# WKUP_ECC_AGGR0_REGS register map
Vendor: Texas Instruments
Peripheral module from a debugger description file (folder J721S2).
Registers are 32-bit, access not given, reset 0x0 unless marked. A register's access mark holds for its fields unless they carry their own. Offsets are as the file gives them; lines under a group give offsets from that group; [hi:lo] are bit positions; {n}, {i} and the like mark numbered series; 'fields as' and 'values as' point back to an identical list; <NAME> marks a mode.

## WKUP_ECC_AGGR0_REGS
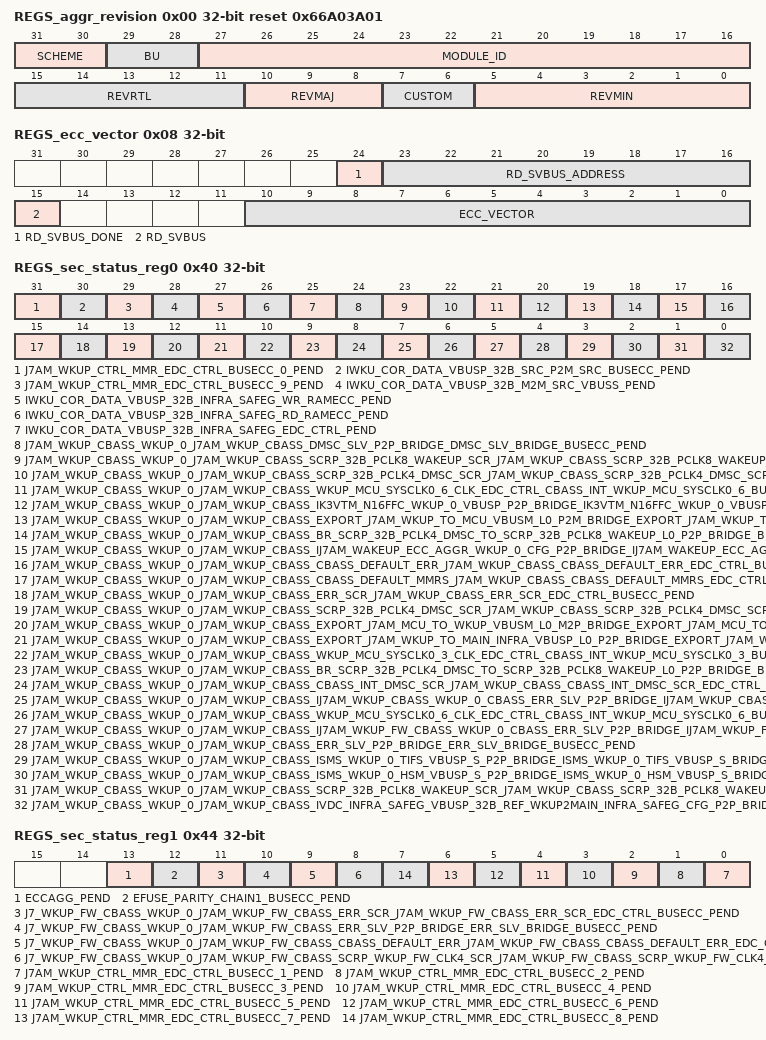
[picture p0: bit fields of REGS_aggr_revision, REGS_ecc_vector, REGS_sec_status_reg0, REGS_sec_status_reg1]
0x00 REGS_aggr_revision ro reset 0x66A03A01 — Revision parameters
  [31:30] SCHEME
  [29:28] BU
  [27:16] MODULE_ID
  [15:11] REVRTL — RTL version
  [10:8] REVMAJ — Major version
  [7:6] CUSTOM — Custom version
  [5:0] REVMIN — Minor version
0x08 REGS_ecc_vector — ECC Vector Register
  [24] RD_SVBUS_DONE — Status to indicate if read on serial VBUS is complete, write of any value will clear this bit. (access R/W1TC)
  [23:16] RD_SVBUS_ADDRESS rw — Read address
  [15] RD_SVBUS — Write 1 to trigger a read on the serial VBUS (access R/W1TS)
  [10:0] ECC_VECTOR rw — Value written to select the corresponding ECC RAM for control or status
0x0C REGS_misc_status ro reset 0x2E — Misc Status
  [10:0] NUM_RAMS — Indicates the number of RAMS serviced by the ECC aggregator
0x10 REGS_reserved_svbus rw — Reference other documents that contain the ECC RAM wrapper and EDC controller serial vbus register sets.
  [31:0] DATA — Serial VBUS register data
0x3C REGS_sec_eoi_reg — EOI Register
  [0] EOI_WR — EOI Register (access R/W1TS)
0x40 REGS_sec_status_reg0 — Interrupt Status Register 0
  [31] J7AM_WKUP_CTRL_MMR_EDC_CTRL_BUSECC_0_PEND — Interrupt Pending Status for j7am_wkup_ctrl_mmr_edc_ctrl_busecc_0_pend (access R/W1TS)
  [30] IWKU_COR_DATA_VBUSP_32B_SRC_P2M_SRC_BUSECC_PEND — Interrupt Pending Status for Iwku_cor_data_vbusp_32b_src_p2m_src_busecc_pend (access R/W1TS)
  [29] J7AM_WKUP_CTRL_MMR_EDC_CTRL_BUSECC_9_PEND — Interrupt Pending Status for j7am_wkup_ctrl_mmr_edc_ctrl_busecc_9_pend (access R/W1TS)
  [28] IWKU_COR_DATA_VBUSP_32B_M2M_SRC_VBUSS_PEND — Interrupt Pending Status for Iwku_cor_data_vbusp_32b_m2m_src_vbuss_pend (access R/W1TS)
  [27] IWKU_COR_DATA_VBUSP_32B_INFRA_SAFEG_WR_RAMECC_PEND — Interrupt Pending Status for Iwku_cor_data_vbusp_32b_infra_safeg_wr_ramecc_pend (access R/W1TS)
  [26] IWKU_COR_DATA_VBUSP_32B_INFRA_SAFEG_RD_RAMECC_PEND — Interrupt Pending Status for Iwku_cor_data_vbusp_32b_infra_safeg_rd_ramecc_pend (access R/W1TS)
  [25] IWKU_COR_DATA_VBUSP_32B_INFRA_SAFEG_EDC_CTRL_PEND — Interrupt Pending Status for Iwku_cor_data_vbusp_32b_infra_safeg_edc_ctrl_pend (access R/W1TS)
  [24] J7AM_WKUP_CBASS_WKUP_0_J7AM_WKUP_CBASS_DMSC_SLV_P2P_BRIDGE_DMSC_SLV_BRIDGE_BUSECC_PEND — Interrupt Pending Status for j7am_wkup_cbass_wkup_0_j7am_wkup_cbass_dmsc_slv_p2p_bridge_dmsc_slv_bridge_busecc_pend (access R/W1TS)
  [23] J7AM_WKUP_CBASS_WKUP_0_J7AM_WKUP_CBASS_SCRP_32B_PCLK8_WAKEUP_SCR_J7AM_WKUP_CBASS_SCRP_32B_PCLK8_WAKEUP_SCR_EDC_CTRL_BUSECC_0_PEND — Interrupt Pending Status for j7am_wkup_cbass_wkup_0_j7am_wkup_cbass_SCRP_32b_PCLK8_wakeup_scr_j7am_wkup_cbass_SCRP_32b_PCLK8_wakeup_scr_edc_ctrl_busecc_0_pend (access R/W1TS)
  [22] J7AM_WKUP_CBASS_WKUP_0_J7AM_WKUP_CBASS_SCRP_32B_PCLK4_DMSC_SCR_J7AM_WKUP_CBASS_SCRP_32B_PCLK4_DMSC_SCR_EDC_CTRL_BUSECC_1_PEND — Interrupt Pending Status for j7am_wkup_cbass_wkup_0_j7am_wkup_cbass_SCRP_32b_PCLK4_DMSC_scr_j7am_wkup_cbass_SCRP_32b_PCLK4_DMSC_scr_edc_ctrl_busecc_1_pend (access R/W1TS)
  [21] J7AM_WKUP_CBASS_WKUP_0_J7AM_WKUP_CBASS_WKUP_MCU_SYSCLK0_6_CLK_EDC_CTRL_CBASS_INT_WKUP_MCU_SYSCLK0_6_BUSECC_1_PEND — Interrupt Pending Status for j7am_wkup_cbass_wkup_0_j7am_wkup_cbass_wkup_mcu_sysclk0_6_clk_edc_ctrl_cbass_int_wkup_mcu_sysclk0_6_busecc_1_pend (access R/W1TS)
  [20] J7AM_WKUP_CBASS_WKUP_0_J7AM_WKUP_CBASS_IK3VTM_N16FFC_WKUP_0_VBUSP_P2P_BRIDGE_IK3VTM_N16FFC_WKUP_0_VBUSP_BRIDGE_BUSECC_PEND — Interrupt Pending Status for j7am_wkup_cbass_wkup_0_j7am_wkup_cbass_Ik3vtm_n16ffc_wkup_0_vbusp_p2p_bridge_Ik3vtm_n16ffc_wkup_0_vbusp_bridge_busecc_pend (access R/W1TS)
  [19] J7AM_WKUP_CBASS_WKUP_0_J7AM_WKUP_CBASS_EXPORT_J7AM_WKUP_TO_MCU_VBUSM_L0_P2M_BRIDGE_EXPORT_J7AM_WKUP_TO_MCU_VBUSM_L0_BRIDGE_BUSECC_PEND — Interrupt Pending Status for j7am_wkup_cbass_wkup_0_j7am_wkup_cbass_export_j7am_wkup_to_mcu_vbusm_l0_p2m_bridge_export_j7am_wkup_to_mcu_vbusm_l0_bridge_busecc_pend (access R/W1TS)
  [18] J7AM_WKUP_CBASS_WKUP_0_J7AM_WKUP_CBASS_BR_SCRP_32B_PCLK4_DMSC_TO_SCRP_32B_PCLK8_WAKEUP_L0_P2P_BRIDGE_BR_SCRP_32B_PCLK4_DMSC_TO_SCRP_32B_PCLK8_WAKEUP_L0_BRIDGE_DST_BUSECC_PEND — Interrupt Pending Status for j7am_wkup_cbass_wkup_0_j7am_wkup_cbass_br_SCRP_32b_PCLK4_DMSC_to_SCRP_32b_PCLK8_wakeup_l0_p2p_bridge_br_SCRP_32b_PCLK4_DMSC_to_SCRP_32b_PCLK8_wakeup_l0_bridge_dst_busecc_pend (access R/W1TS)
  [17] J7AM_WKUP_CBASS_WKUP_0_J7AM_WKUP_CBASS_IJ7AM_WAKEUP_ECC_AGGR_WKUP_0_CFG_P2P_BRIDGE_IJ7AM_WAKEUP_ECC_AGGR_WKUP_0_CFG_BRIDGE_BUSECC_PEND — Interrupt Pending Status for j7am_wkup_cbass_wkup_0_j7am_wkup_cbass_Ij7am_wakeup_ecc_aggr_wkup_0_cfg_p2p_bridge_Ij7am_wakeup_ecc_aggr_wkup_0_cfg_bridge_busecc_pend (access R/W1TS)
  [16] J7AM_WKUP_CBASS_WKUP_0_J7AM_WKUP_CBASS_CBASS_DEFAULT_ERR_J7AM_WKUP_CBASS_CBASS_DEFAULT_ERR_EDC_CTRL_BUSECC_PEND — Interrupt Pending Status for j7am_wkup_cbass_wkup_0_j7am_wkup_cbass_cbass_default_err_j7am_wkup_cbass_cbass_default_err_edc_ctrl_busecc_pend (access R/W1TS)
  [15] J7AM_WKUP_CBASS_WKUP_0_J7AM_WKUP_CBASS_CBASS_DEFAULT_MMRS_J7AM_WKUP_CBASS_CBASS_DEFAULT_MMRS_EDC_CTRL_BUSECC_PEND — Interrupt Pending Status for j7am_wkup_cbass_wkup_0_j7am_wkup_cbass_cbass_default_mmrs_j7am_wkup_cbass_cbass_default_mmrs_edc_ctrl_busecc_pend (access R/W1TS)
  [14] J7AM_WKUP_CBASS_WKUP_0_J7AM_WKUP_CBASS_ERR_SCR_J7AM_WKUP_CBASS_ERR_SCR_EDC_CTRL_BUSECC_PEND — Interrupt Pending Status for j7am_wkup_cbass_wkup_0_j7am_wkup_cbass_err_scr_j7am_wkup_cbass_err_scr_edc_ctrl_busecc_pend (access R/W1TS)
  [13] J7AM_WKUP_CBASS_WKUP_0_J7AM_WKUP_CBASS_SCRP_32B_PCLK4_DMSC_SCR_J7AM_WKUP_CBASS_SCRP_32B_PCLK4_DMSC_SCR_EDC_CTRL_BUSECC_0_PEND — Interrupt Pending Status for j7am_wkup_cbass_wkup_0_j7am_wkup_cbass_SCRP_32b_PCLK4_DMSC_scr_j7am_wkup_cbass_SCRP_32b_PCLK4_DMSC_scr_edc_ctrl_busecc_0_pend (access R/W1TS)
  [12] J7AM_WKUP_CBASS_WKUP_0_J7AM_WKUP_CBASS_EXPORT_J7AM_MCU_TO_WKUP_VBUSM_L0_M2P_BRIDGE_EXPORT_J7AM_MCU_TO_WKUP_VBUSM_L0_BRIDGE_BUSECC_PEND — Interrupt Pending Status for j7am_wkup_cbass_wkup_0_j7am_wkup_cbass_export_j7am_mcu_to_wkup_vbusm_l0_m2p_bridge_export_j7am_mcu_to_wkup_vbusm_l0_bridge_busecc_pend (access R/W1TS)
  [11] J7AM_WKUP_CBASS_WKUP_0_J7AM_WKUP_CBASS_EXPORT_J7AM_WKUP_TO_MAIN_INFRA_VBUSP_L0_P2P_BRIDGE_EXPORT_J7AM_WKUP_TO_MAIN_INFRA_VBUSP_L0_BRIDGE_BUSECC_PEND — Interrupt Pending Status for j7am_wkup_cbass_wkup_0_j7am_wkup_cbass_export_j7am_wkup_to_main_infra_vbusp_l0_p2p_bridge_export_j7am_wkup_to_main_infra_vbusp_l0_bridge_busecc_pend (access R/W1TS)
  [10] J7AM_WKUP_CBASS_WKUP_0_J7AM_WKUP_CBASS_WKUP_MCU_SYSCLK0_3_CLK_EDC_CTRL_CBASS_INT_WKUP_MCU_SYSCLK0_3_BUSECC_PEND — Interrupt Pending Status for j7am_wkup_cbass_wkup_0_j7am_wkup_cbass_wkup_mcu_sysclk0_3_clk_edc_ctrl_cbass_int_wkup_mcu_sysclk0_3_busecc_pend (access R/W1TS)
  [9] J7AM_WKUP_CBASS_WKUP_0_J7AM_WKUP_CBASS_BR_SCRP_32B_PCLK4_DMSC_TO_SCRP_32B_PCLK8_WAKEUP_L0_P2P_BRIDGE_BR_SCRP_32B_PCLK4_DMSC_TO_SCRP_32B_PCLK8_WAKEUP_L0_BRIDGE_SRC_BUSECC_PEND — Interrupt Pending Status for j7am_wkup_cbass_wkup_0_j7am_wkup_cbass_br_SCRP_32b_PCLK4_DMSC_to_SCRP_32b_PCLK8_wakeup_l0_p2p_bridge_br_SCRP_32b_PCLK4_DMSC_to_SCRP_32b_PCLK8_wakeup_l0_bridge_src_busecc_pend (access R/W1TS)
  [8] J7AM_WKUP_CBASS_WKUP_0_J7AM_WKUP_CBASS_CBASS_INT_DMSC_SCR_J7AM_WKUP_CBASS_CBASS_INT_DMSC_SCR_EDC_CTRL_BUSECC_PEND — Interrupt Pending Status for j7am_wkup_cbass_wkup_0_j7am_wkup_cbass_cbass_int_dmsc_scr_j7am_wkup_cbass_cbass_int_dmsc_scr_edc_ctrl_busecc_pend (access R/W1TS)
  [7] J7AM_WKUP_CBASS_WKUP_0_J7AM_WKUP_CBASS_IJ7AM_WKUP_CBASS_WKUP_0_CBASS_ERR_SLV_P2P_BRIDGE_IJ7AM_WKUP_CBASS_WKUP_0_CBASS_ERR_SLV_BRIDGE_BUSECC_PEND — Interrupt Pending Status for j7am_wkup_cbass_wkup_0_j7am_wkup_cbass_Ij7am_wkup_cbass_wkup_0_cbass_err_slv_p2p_bridge_Ij7am_wkup_cbass_wkup_0_cbass_err_slv_bridge_busecc_pend (access R/W1TS)
  [6] J7AM_WKUP_CBASS_WKUP_0_J7AM_WKUP_CBASS_WKUP_MCU_SYSCLK0_6_CLK_EDC_CTRL_CBASS_INT_WKUP_MCU_SYSCLK0_6_BUSECC_0_PEND — Interrupt Pending Status for j7am_wkup_cbass_wkup_0_j7am_wkup_cbass_wkup_mcu_sysclk0_6_clk_edc_ctrl_cbass_int_wkup_mcu_sysclk0_6_busecc_0_pend (access R/W1TS)
  [5] J7AM_WKUP_CBASS_WKUP_0_J7AM_WKUP_CBASS_IJ7AM_WKUP_FW_CBASS_WKUP_0_CBASS_ERR_SLV_P2P_BRIDGE_IJ7AM_WKUP_FW_CBASS_WKUP_0_CBASS_ERR_SLV_BRIDGE_BUSECC_PEND — Interrupt Pending Status for j7am_wkup_cbass_wkup_0_j7am_wkup_cbass_Ij7am_wkup_fw_cbass_wkup_0_cbass_err_slv_p2p_bridge_Ij7am_wkup_fw_cbass_wkup_0_cbass_err_slv_bridge_busecc_pend (access R/W1TS)
  [4] J7AM_WKUP_CBASS_WKUP_0_J7AM_WKUP_CBASS_ERR_SLV_P2P_BRIDGE_ERR_SLV_BRIDGE_BUSECC_PEND — Interrupt Pending Status for j7am_wkup_cbass_wkup_0_j7am_wkup_cbass_err_slv_p2p_bridge_err_slv_bridge_busecc_pend (access R/W1TS)
  [3] J7AM_WKUP_CBASS_WKUP_0_J7AM_WKUP_CBASS_ISMS_WKUP_0_TIFS_VBUSP_S_P2P_BRIDGE_ISMS_WKUP_0_TIFS_VBUSP_S_BRIDGE_BUSECC_PEND — Interrupt Pending Status for j7am_wkup_cbass_wkup_0_j7am_wkup_cbass_Isms_wkup_0_tifs_vbusp_s_p2p_bridge_Isms_wkup_0_tifs_vbusp_s_bridge_busecc_pend (access R/W1TS)
  [2] J7AM_WKUP_CBASS_WKUP_0_J7AM_WKUP_CBASS_ISMS_WKUP_0_HSM_VBUSP_S_P2P_BRIDGE_ISMS_WKUP_0_HSM_VBUSP_S_BRIDGE_BUSECC_PEND — Interrupt Pending Status for j7am_wkup_cbass_wkup_0_j7am_wkup_cbass_Isms_wkup_0_hsm_vbusp_s_p2p_bridge_Isms_wkup_0_hsm_vbusp_s_bridge_busecc_pend (access R/W1TS)
  [1] J7AM_WKUP_CBASS_WKUP_0_J7AM_WKUP_CBASS_SCRP_32B_PCLK8_WAKEUP_SCR_J7AM_WKUP_CBASS_SCRP_32B_PCLK8_WAKEUP_SCR_EDC_CTRL_BUSECC_1_PEND — Interrupt Pending Status for j7am_wkup_cbass_wkup_0_j7am_wkup_cbass_SCRP_32b_PCLK8_wakeup_scr_j7am_wkup_cbass_SCRP_32b_PCLK8_wakeup_scr_edc_ctrl_busecc_1_pend (access R/W1TS)
  [0] J7AM_WKUP_CBASS_WKUP_0_J7AM_WKUP_CBASS_IVDC_INFRA_SAFEG_VBUSP_32B_REF_WKUP2MAIN_INFRA_SAFEG_CFG_P2P_BRIDGE_IVDC_INFRA_SAFEG_VBUSP_32B_REF_WKUP2MAIN_INFRA_SAFEG_CFG_BRIDGE_BUSECC_PEND — Interrupt Pending Status for j7am_wkup_cbass_wkup_0_j7am_wkup_cbass_Ivdc_infra_safeg_vbusp_32b_ref_wkup2main_infra_safeg_cfg_p2p_bridge_Ivdc_infra_safeg_vbusp_32b_ref_wkup2main_infra_safeg_cfg_bridge_busecc_pend (access R/W1TS)
0x44 REGS_sec_status_reg1 — Interrupt Status Register 1
  [13] ECCAGG_PEND — Interrupt Pending Status for eccagg_pend (access R/W1TS)
  [12] EFUSE_PARITY_CHAIN1_BUSECC_PEND — Interrupt Pending Status for efuse_parity_chain1_busecc_pend (access R/W1TS)
  [11] J7_WKUP_FW_CBASS_WKUP_0_J7AM_WKUP_FW_CBASS_ERR_SCR_J7AM_WKUP_FW_CBASS_ERR_SCR_EDC_CTRL_BUSECC_PEND — Interrupt Pending Status for j7_wkup_fw_cbass_wkup_0_j7am_wkup_fw_cbass_err_scr_j7am_wkup_fw_cbass_err_scr_edc_ctrl_busecc_pend (access R/W1TS)
  [10] J7_WKUP_FW_CBASS_WKUP_0_J7AM_WKUP_FW_CBASS_ERR_SLV_P2P_BRIDGE_ERR_SLV_BRIDGE_BUSECC_PEND — Interrupt Pending Status for j7_wkup_fw_cbass_wkup_0_j7am_wkup_fw_cbass_err_slv_p2p_bridge_err_slv_bridge_busecc_pend (access R/W1TS)
  [9] J7_WKUP_FW_CBASS_WKUP_0_J7AM_WKUP_FW_CBASS_CBASS_DEFAULT_ERR_J7AM_WKUP_FW_CBASS_CBASS_DEFAULT_ERR_EDC_CTRL_BUSECC_PEND — Interrupt Pending Status for j7_wkup_fw_cbass_wkup_0_j7am_wkup_fw_cbass_cbass_default_err_j7am_wkup_fw_cbass_cbass_default_err_edc_ctrl_busecc_pend (access R/W1TS)
  [8] J7_WKUP_FW_CBASS_WKUP_0_J7AM_WKUP_FW_CBASS_SCRP_WKUP_FW_CLK4_SCR_J7AM_WKUP_FW_CBASS_SCRP_WKUP_FW_CLK4_SCR_EDC_CTRL_BUSECC_PEND — Interrupt Pending Status for j7_wkup_fw_cbass_wkup_0_j7am_wkup_fw_cbass_SCRP_wkup_fw_CLK4_scr_j7am_wkup_fw_cbass_SCRP_wkup_fw_CLK4_scr_edc_ctrl_busecc_pend (access R/W1TS)
  [n-1] J7AM_WKUP_CTRL_MMR_EDC_CTRL_BUSECC_{n}_PEND (n=1..8) — Interrupt Pending Status for j7am_wkup_ctrl_mmr_edc_ctrl_busecc_{n}_pend (access R/W1TS)
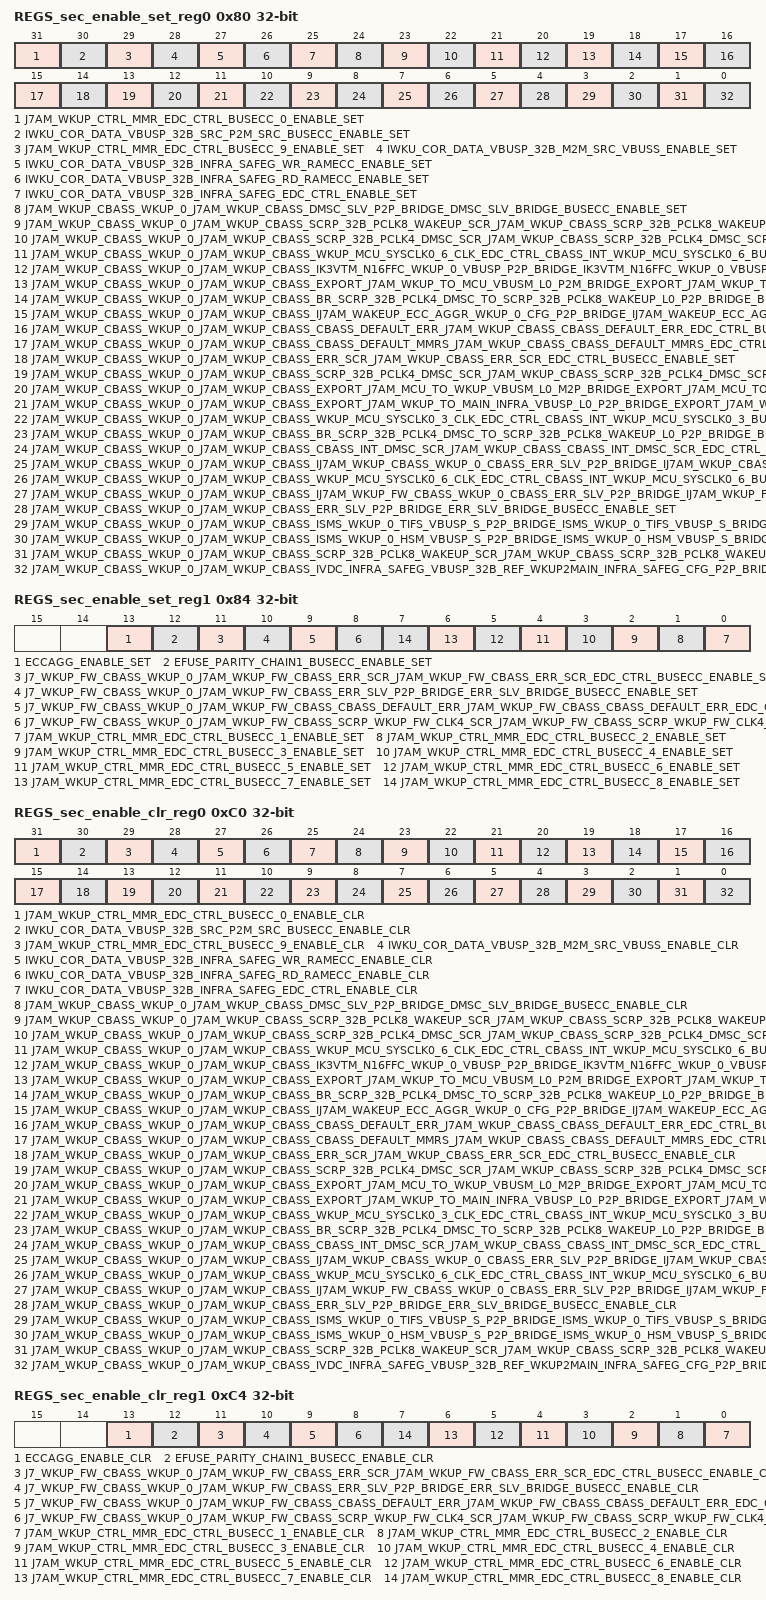
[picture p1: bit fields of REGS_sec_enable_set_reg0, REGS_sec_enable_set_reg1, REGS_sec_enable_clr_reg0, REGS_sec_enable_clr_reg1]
0x80 REGS_sec_enable_set_reg0 — Interrupt Enable Set Register 0
  [31] J7AM_WKUP_CTRL_MMR_EDC_CTRL_BUSECC_0_ENABLE_SET — Interrupt Enable Set Register for j7am_wkup_ctrl_mmr_edc_ctrl_busecc_0_pend (access R/W1TS)
  [30] IWKU_COR_DATA_VBUSP_32B_SRC_P2M_SRC_BUSECC_ENABLE_SET — Interrupt Enable Set Register for Iwku_cor_data_vbusp_32b_src_p2m_src_busecc_pend (access R/W1TS)
  [29] J7AM_WKUP_CTRL_MMR_EDC_CTRL_BUSECC_9_ENABLE_SET — Interrupt Enable Set Register for j7am_wkup_ctrl_mmr_edc_ctrl_busecc_9_pend (access R/W1TS)
  [28] IWKU_COR_DATA_VBUSP_32B_M2M_SRC_VBUSS_ENABLE_SET — Interrupt Enable Set Register for Iwku_cor_data_vbusp_32b_m2m_src_vbuss_pend (access R/W1TS)
  [27] IWKU_COR_DATA_VBUSP_32B_INFRA_SAFEG_WR_RAMECC_ENABLE_SET — Interrupt Enable Set Register for Iwku_cor_data_vbusp_32b_infra_safeg_wr_ramecc_pend (access R/W1TS)
  [26] IWKU_COR_DATA_VBUSP_32B_INFRA_SAFEG_RD_RAMECC_ENABLE_SET — Interrupt Enable Set Register for Iwku_cor_data_vbusp_32b_infra_safeg_rd_ramecc_pend (access R/W1TS)
  [25] IWKU_COR_DATA_VBUSP_32B_INFRA_SAFEG_EDC_CTRL_ENABLE_SET — Interrupt Enable Set Register for Iwku_cor_data_vbusp_32b_infra_safeg_edc_ctrl_pend (access R/W1TS)
  [24] J7AM_WKUP_CBASS_WKUP_0_J7AM_WKUP_CBASS_DMSC_SLV_P2P_BRIDGE_DMSC_SLV_BRIDGE_BUSECC_ENABLE_SET — Interrupt Enable Set Register for j7am_wkup_cbass_wkup_0_j7am_wkup_cbass_dmsc_slv_p2p_bridge_dmsc_slv_bridge_busecc_pend (access R/W1TS)
  [23] J7AM_WKUP_CBASS_WKUP_0_J7AM_WKUP_CBASS_SCRP_32B_PCLK8_WAKEUP_SCR_J7AM_WKUP_CBASS_SCRP_32B_PCLK8_WAKEUP_SCR_EDC_CTRL_BUSECC_0_ENABLE_SET — Interrupt Enable Set Register for j7am_wkup_cbass_wkup_0_j7am_wkup_cbass_SCRP_32b_PCLK8_wakeup_scr_j7am_wkup_cbass_SCRP_32b_PCLK8_wakeup_scr_edc_ctrl_busecc_0_pend (access R/W1TS)
  [22] J7AM_WKUP_CBASS_WKUP_0_J7AM_WKUP_CBASS_SCRP_32B_PCLK4_DMSC_SCR_J7AM_WKUP_CBASS_SCRP_32B_PCLK4_DMSC_SCR_EDC_CTRL_BUSECC_1_ENABLE_SET — Interrupt Enable Set Register for j7am_wkup_cbass_wkup_0_j7am_wkup_cbass_SCRP_32b_PCLK4_DMSC_scr_j7am_wkup_cbass_SCRP_32b_PCLK4_DMSC_scr_edc_ctrl_busecc_1_pend (access R/W1TS)
  [21] J7AM_WKUP_CBASS_WKUP_0_J7AM_WKUP_CBASS_WKUP_MCU_SYSCLK0_6_CLK_EDC_CTRL_CBASS_INT_WKUP_MCU_SYSCLK0_6_BUSECC_1_ENABLE_SET — Interrupt Enable Set Register for j7am_wkup_cbass_wkup_0_j7am_wkup_cbass_wkup_mcu_sysclk0_6_clk_edc_ctrl_cbass_int_wkup_mcu_sysclk0_6_busecc_1_pend (access R/W1TS)
  [20] J7AM_WKUP_CBASS_WKUP_0_J7AM_WKUP_CBASS_IK3VTM_N16FFC_WKUP_0_VBUSP_P2P_BRIDGE_IK3VTM_N16FFC_WKUP_0_VBUSP_BRIDGE_BUSECC_ENABLE_SET — Interrupt Enable Set Register for j7am_wkup_cbass_wkup_0_j7am_wkup_cbass_Ik3vtm_n16ffc_wkup_0_vbusp_p2p_bridge_Ik3vtm_n16ffc_wkup_0_vbusp_bridge_busecc_pend (access R/W1TS)
  [19] J7AM_WKUP_CBASS_WKUP_0_J7AM_WKUP_CBASS_EXPORT_J7AM_WKUP_TO_MCU_VBUSM_L0_P2M_BRIDGE_EXPORT_J7AM_WKUP_TO_MCU_VBUSM_L0_BRIDGE_BUSECC_ENABLE_SET — Interrupt Enable Set Register for j7am_wkup_cbass_wkup_0_j7am_wkup_cbass_export_j7am_wkup_to_mcu_vbusm_l0_p2m_bridge_export_j7am_wkup_to_mcu_vbusm_l0_bridge_busecc_pend (access R/W1TS)
  [18] J7AM_WKUP_CBASS_WKUP_0_J7AM_WKUP_CBASS_BR_SCRP_32B_PCLK4_DMSC_TO_SCRP_32B_PCLK8_WAKEUP_L0_P2P_BRIDGE_BR_SCRP_32B_PCLK4_DMSC_TO_SCRP_32B_PCLK8_WAKEUP_L0_BRIDGE_DST_BUSECC_ENABLE_SET — Interrupt Enable Set Register for j7am_wkup_cbass_wkup_0_j7am_wkup_cbass_br_SCRP_32b_PCLK4_DMSC_to_SCRP_32b_PCLK8_wakeup_l0_p2p_bridge_br_SCRP_32b_PCLK4_DMSC_to_SCRP_32b_PCLK8_wakeup_l0_bridge_dst_busecc_pend (access R/W1TS)
  [17] J7AM_WKUP_CBASS_WKUP_0_J7AM_WKUP_CBASS_IJ7AM_WAKEUP_ECC_AGGR_WKUP_0_CFG_P2P_BRIDGE_IJ7AM_WAKEUP_ECC_AGGR_WKUP_0_CFG_BRIDGE_BUSECC_ENABLE_SET — Interrupt Enable Set Register for j7am_wkup_cbass_wkup_0_j7am_wkup_cbass_Ij7am_wakeup_ecc_aggr_wkup_0_cfg_p2p_bridge_Ij7am_wakeup_ecc_aggr_wkup_0_cfg_bridge_busecc_pend (access R/W1TS)
  [16] J7AM_WKUP_CBASS_WKUP_0_J7AM_WKUP_CBASS_CBASS_DEFAULT_ERR_J7AM_WKUP_CBASS_CBASS_DEFAULT_ERR_EDC_CTRL_BUSECC_ENABLE_SET — Interrupt Enable Set Register for j7am_wkup_cbass_wkup_0_j7am_wkup_cbass_cbass_default_err_j7am_wkup_cbass_cbass_default_err_edc_ctrl_busecc_pend (access R/W1TS)
  [15] J7AM_WKUP_CBASS_WKUP_0_J7AM_WKUP_CBASS_CBASS_DEFAULT_MMRS_J7AM_WKUP_CBASS_CBASS_DEFAULT_MMRS_EDC_CTRL_BUSECC_ENABLE_SET — Interrupt Enable Set Register for j7am_wkup_cbass_wkup_0_j7am_wkup_cbass_cbass_default_mmrs_j7am_wkup_cbass_cbass_default_mmrs_edc_ctrl_busecc_pend (access R/W1TS)
  [14] J7AM_WKUP_CBASS_WKUP_0_J7AM_WKUP_CBASS_ERR_SCR_J7AM_WKUP_CBASS_ERR_SCR_EDC_CTRL_BUSECC_ENABLE_SET — Interrupt Enable Set Register for j7am_wkup_cbass_wkup_0_j7am_wkup_cbass_err_scr_j7am_wkup_cbass_err_scr_edc_ctrl_busecc_pend (access R/W1TS)
  [13] J7AM_WKUP_CBASS_WKUP_0_J7AM_WKUP_CBASS_SCRP_32B_PCLK4_DMSC_SCR_J7AM_WKUP_CBASS_SCRP_32B_PCLK4_DMSC_SCR_EDC_CTRL_BUSECC_0_ENABLE_SET — Interrupt Enable Set Register for j7am_wkup_cbass_wkup_0_j7am_wkup_cbass_SCRP_32b_PCLK4_DMSC_scr_j7am_wkup_cbass_SCRP_32b_PCLK4_DMSC_scr_edc_ctrl_busecc_0_pend (access R/W1TS)
  [12] J7AM_WKUP_CBASS_WKUP_0_J7AM_WKUP_CBASS_EXPORT_J7AM_MCU_TO_WKUP_VBUSM_L0_M2P_BRIDGE_EXPORT_J7AM_MCU_TO_WKUP_VBUSM_L0_BRIDGE_BUSECC_ENABLE_SET — Interrupt Enable Set Register for j7am_wkup_cbass_wkup_0_j7am_wkup_cbass_export_j7am_mcu_to_wkup_vbusm_l0_m2p_bridge_export_j7am_mcu_to_wkup_vbusm_l0_bridge_busecc_pend (access R/W1TS)
  [11] J7AM_WKUP_CBASS_WKUP_0_J7AM_WKUP_CBASS_EXPORT_J7AM_WKUP_TO_MAIN_INFRA_VBUSP_L0_P2P_BRIDGE_EXPORT_J7AM_WKUP_TO_MAIN_INFRA_VBUSP_L0_BRIDGE_BUSECC_ENABLE_SET — Interrupt Enable Set Register for j7am_wkup_cbass_wkup_0_j7am_wkup_cbass_export_j7am_wkup_to_main_infra_vbusp_l0_p2p_bridge_export_j7am_wkup_to_main_infra_vbusp_l0_bridge_busecc_pend (access R/W1TS)
  [10] J7AM_WKUP_CBASS_WKUP_0_J7AM_WKUP_CBASS_WKUP_MCU_SYSCLK0_3_CLK_EDC_CTRL_CBASS_INT_WKUP_MCU_SYSCLK0_3_BUSECC_ENABLE_SET — Interrupt Enable Set Register for j7am_wkup_cbass_wkup_0_j7am_wkup_cbass_wkup_mcu_sysclk0_3_clk_edc_ctrl_cbass_int_wkup_mcu_sysclk0_3_busecc_pend (access R/W1TS)
  [9] J7AM_WKUP_CBASS_WKUP_0_J7AM_WKUP_CBASS_BR_SCRP_32B_PCLK4_DMSC_TO_SCRP_32B_PCLK8_WAKEUP_L0_P2P_BRIDGE_BR_SCRP_32B_PCLK4_DMSC_TO_SCRP_32B_PCLK8_WAKEUP_L0_BRIDGE_SRC_BUSECC_ENABLE_SET — Interrupt Enable Set Register for j7am_wkup_cbass_wkup_0_j7am_wkup_cbass_br_SCRP_32b_PCLK4_DMSC_to_SCRP_32b_PCLK8_wakeup_l0_p2p_bridge_br_SCRP_32b_PCLK4_DMSC_to_SCRP_32b_PCLK8_wakeup_l0_bridge_src_busecc_pend (access R/W1TS)
  [8] J7AM_WKUP_CBASS_WKUP_0_J7AM_WKUP_CBASS_CBASS_INT_DMSC_SCR_J7AM_WKUP_CBASS_CBASS_INT_DMSC_SCR_EDC_CTRL_BUSECC_ENABLE_SET — Interrupt Enable Set Register for j7am_wkup_cbass_wkup_0_j7am_wkup_cbass_cbass_int_dmsc_scr_j7am_wkup_cbass_cbass_int_dmsc_scr_edc_ctrl_busecc_pend (access R/W1TS)
  [7] J7AM_WKUP_CBASS_WKUP_0_J7AM_WKUP_CBASS_IJ7AM_WKUP_CBASS_WKUP_0_CBASS_ERR_SLV_P2P_BRIDGE_IJ7AM_WKUP_CBASS_WKUP_0_CBASS_ERR_SLV_BRIDGE_BUSECC_ENABLE_SET — Interrupt Enable Set Register for j7am_wkup_cbass_wkup_0_j7am_wkup_cbass_Ij7am_wkup_cbass_wkup_0_cbass_err_slv_p2p_bridge_Ij7am_wkup_cbass_wkup_0_cbass_err_slv_bridge_busecc_pend (access R/W1TS)
  [6] J7AM_WKUP_CBASS_WKUP_0_J7AM_WKUP_CBASS_WKUP_MCU_SYSCLK0_6_CLK_EDC_CTRL_CBASS_INT_WKUP_MCU_SYSCLK0_6_BUSECC_0_ENABLE_SET — Interrupt Enable Set Register for j7am_wkup_cbass_wkup_0_j7am_wkup_cbass_wkup_mcu_sysclk0_6_clk_edc_ctrl_cbass_int_wkup_mcu_sysclk0_6_busecc_0_pend (access R/W1TS)
  [5] J7AM_WKUP_CBASS_WKUP_0_J7AM_WKUP_CBASS_IJ7AM_WKUP_FW_CBASS_WKUP_0_CBASS_ERR_SLV_P2P_BRIDGE_IJ7AM_WKUP_FW_CBASS_WKUP_0_CBASS_ERR_SLV_BRIDGE_BUSECC_ENABLE_SET — Interrupt Enable Set Register for j7am_wkup_cbass_wkup_0_j7am_wkup_cbass_Ij7am_wkup_fw_cbass_wkup_0_cbass_err_slv_p2p_bridge_Ij7am_wkup_fw_cbass_wkup_0_cbass_err_slv_bridge_busecc_pend (access R/W1TS)
  [4] J7AM_WKUP_CBASS_WKUP_0_J7AM_WKUP_CBASS_ERR_SLV_P2P_BRIDGE_ERR_SLV_BRIDGE_BUSECC_ENABLE_SET — Interrupt Enable Set Register for j7am_wkup_cbass_wkup_0_j7am_wkup_cbass_err_slv_p2p_bridge_err_slv_bridge_busecc_pend (access R/W1TS)
  [3] J7AM_WKUP_CBASS_WKUP_0_J7AM_WKUP_CBASS_ISMS_WKUP_0_TIFS_VBUSP_S_P2P_BRIDGE_ISMS_WKUP_0_TIFS_VBUSP_S_BRIDGE_BUSECC_ENABLE_SET — Interrupt Enable Set Register for j7am_wkup_cbass_wkup_0_j7am_wkup_cbass_Isms_wkup_0_tifs_vbusp_s_p2p_bridge_Isms_wkup_0_tifs_vbusp_s_bridge_busecc_pend (access R/W1TS)
  [2] J7AM_WKUP_CBASS_WKUP_0_J7AM_WKUP_CBASS_ISMS_WKUP_0_HSM_VBUSP_S_P2P_BRIDGE_ISMS_WKUP_0_HSM_VBUSP_S_BRIDGE_BUSECC_ENABLE_SET — Interrupt Enable Set Register for j7am_wkup_cbass_wkup_0_j7am_wkup_cbass_Isms_wkup_0_hsm_vbusp_s_p2p_bridge_Isms_wkup_0_hsm_vbusp_s_bridge_busecc_pend (access R/W1TS)
  [1] J7AM_WKUP_CBASS_WKUP_0_J7AM_WKUP_CBASS_SCRP_32B_PCLK8_WAKEUP_SCR_J7AM_WKUP_CBASS_SCRP_32B_PCLK8_WAKEUP_SCR_EDC_CTRL_BUSECC_1_ENABLE_SET — Interrupt Enable Set Register for j7am_wkup_cbass_wkup_0_j7am_wkup_cbass_SCRP_32b_PCLK8_wakeup_scr_j7am_wkup_cbass_SCRP_32b_PCLK8_wakeup_scr_edc_ctrl_busecc_1_pend (access R/W1TS)
  [0] J7AM_WKUP_CBASS_WKUP_0_J7AM_WKUP_CBASS_IVDC_INFRA_SAFEG_VBUSP_32B_REF_WKUP2MAIN_INFRA_SAFEG_CFG_P2P_BRIDGE_IVDC_INFRA_SAFEG_VBUSP_32B_REF_WKUP2MAIN_INFRA_SAFEG_CFG_BRIDGE_BUSECC_ENABLE_SET — Interrupt Enable Set Register for j7am_wkup_cbass_wkup_0_j7am_wkup_cbass_Ivdc_infra_safeg_vbusp_32b_ref_wkup2main_infra_safeg_cfg_p2p_bridge_Ivdc_infra_safeg_vbusp_32b_ref_wkup2main_infra_safeg_cfg_bridge_busecc_pend (access R/W1TS)
0x84 REGS_sec_enable_set_reg1 — Interrupt Enable Set Register 1
  [13] ECCAGG_ENABLE_SET — Interrupt Enable Set Register for eccagg_pend (access R/W1TS)
  [12] EFUSE_PARITY_CHAIN1_BUSECC_ENABLE_SET — Interrupt Enable Set Register for efuse_parity_chain1_busecc_pend (access R/W1TS)
  [11] J7_WKUP_FW_CBASS_WKUP_0_J7AM_WKUP_FW_CBASS_ERR_SCR_J7AM_WKUP_FW_CBASS_ERR_SCR_EDC_CTRL_BUSECC_ENABLE_SET — Interrupt Enable Set Register for j7_wkup_fw_cbass_wkup_0_j7am_wkup_fw_cbass_err_scr_j7am_wkup_fw_cbass_err_scr_edc_ctrl_busecc_pend (access R/W1TS)
  [10] J7_WKUP_FW_CBASS_WKUP_0_J7AM_WKUP_FW_CBASS_ERR_SLV_P2P_BRIDGE_ERR_SLV_BRIDGE_BUSECC_ENABLE_SET — Interrupt Enable Set Register for j7_wkup_fw_cbass_wkup_0_j7am_wkup_fw_cbass_err_slv_p2p_bridge_err_slv_bridge_busecc_pend (access R/W1TS)
  [9] J7_WKUP_FW_CBASS_WKUP_0_J7AM_WKUP_FW_CBASS_CBASS_DEFAULT_ERR_J7AM_WKUP_FW_CBASS_CBASS_DEFAULT_ERR_EDC_CTRL_BUSECC_ENABLE_SET — Interrupt Enable Set Register for j7_wkup_fw_cbass_wkup_0_j7am_wkup_fw_cbass_cbass_default_err_j7am_wkup_fw_cbass_cbass_default_err_edc_ctrl_busecc_pend (access R/W1TS)
  [8] J7_WKUP_FW_CBASS_WKUP_0_J7AM_WKUP_FW_CBASS_SCRP_WKUP_FW_CLK4_SCR_J7AM_WKUP_FW_CBASS_SCRP_WKUP_FW_CLK4_SCR_EDC_CTRL_BUSECC_ENABLE_SET — Interrupt Enable Set Register for j7_wkup_fw_cbass_wkup_0_j7am_wkup_fw_cbass_SCRP_wkup_fw_CLK4_scr_j7am_wkup_fw_cbass_SCRP_wkup_fw_CLK4_scr_edc_ctrl_busecc_pend (access R/W1TS)
  [n-1] J7AM_WKUP_CTRL_MMR_EDC_CTRL_BUSECC_{n}_ENABLE_SET (n=1..8) — Interrupt Enable Set Register for j7am_wkup_ctrl_mmr_edc_ctrl_busecc_{n}_pend (access R/W1TS)
0xC0 REGS_sec_enable_clr_reg0 — Interrupt Enable Clear Register 0
  [31] J7AM_WKUP_CTRL_MMR_EDC_CTRL_BUSECC_0_ENABLE_CLR — Interrupt Enable Clear Register for j7am_wkup_ctrl_mmr_edc_ctrl_busecc_0_pend (access R/W1TC)
  [30] IWKU_COR_DATA_VBUSP_32B_SRC_P2M_SRC_BUSECC_ENABLE_CLR — Interrupt Enable Clear Register for Iwku_cor_data_vbusp_32b_src_p2m_src_busecc_pend (access R/W1TC)
  [29] J7AM_WKUP_CTRL_MMR_EDC_CTRL_BUSECC_9_ENABLE_CLR — Interrupt Enable Clear Register for j7am_wkup_ctrl_mmr_edc_ctrl_busecc_9_pend (access R/W1TC)
  [28] IWKU_COR_DATA_VBUSP_32B_M2M_SRC_VBUSS_ENABLE_CLR — Interrupt Enable Clear Register for Iwku_cor_data_vbusp_32b_m2m_src_vbuss_pend (access R/W1TC)
  [27] IWKU_COR_DATA_VBUSP_32B_INFRA_SAFEG_WR_RAMECC_ENABLE_CLR — Interrupt Enable Clear Register for Iwku_cor_data_vbusp_32b_infra_safeg_wr_ramecc_pend (access R/W1TC)
  [26] IWKU_COR_DATA_VBUSP_32B_INFRA_SAFEG_RD_RAMECC_ENABLE_CLR — Interrupt Enable Clear Register for Iwku_cor_data_vbusp_32b_infra_safeg_rd_ramecc_pend (access R/W1TC)
  [25] IWKU_COR_DATA_VBUSP_32B_INFRA_SAFEG_EDC_CTRL_ENABLE_CLR — Interrupt Enable Clear Register for Iwku_cor_data_vbusp_32b_infra_safeg_edc_ctrl_pend (access R/W1TC)
  [24] J7AM_WKUP_CBASS_WKUP_0_J7AM_WKUP_CBASS_DMSC_SLV_P2P_BRIDGE_DMSC_SLV_BRIDGE_BUSECC_ENABLE_CLR — Interrupt Enable Clear Register for j7am_wkup_cbass_wkup_0_j7am_wkup_cbass_dmsc_slv_p2p_bridge_dmsc_slv_bridge_busecc_pend (access R/W1TC)
  [23] J7AM_WKUP_CBASS_WKUP_0_J7AM_WKUP_CBASS_SCRP_32B_PCLK8_WAKEUP_SCR_J7AM_WKUP_CBASS_SCRP_32B_PCLK8_WAKEUP_SCR_EDC_CTRL_BUSECC_0_ENABLE_CLR — Interrupt Enable Clear Register for j7am_wkup_cbass_wkup_0_j7am_wkup_cbass_SCRP_32b_PCLK8_wakeup_scr_j7am_wkup_cbass_SCRP_32b_PCLK8_wakeup_scr_edc_ctrl_busecc_0_pend (access R/W1TC)
  [22] J7AM_WKUP_CBASS_WKUP_0_J7AM_WKUP_CBASS_SCRP_32B_PCLK4_DMSC_SCR_J7AM_WKUP_CBASS_SCRP_32B_PCLK4_DMSC_SCR_EDC_CTRL_BUSECC_1_ENABLE_CLR — Interrupt Enable Clear Register for j7am_wkup_cbass_wkup_0_j7am_wkup_cbass_SCRP_32b_PCLK4_DMSC_scr_j7am_wkup_cbass_SCRP_32b_PCLK4_DMSC_scr_edc_ctrl_busecc_1_pend (access R/W1TC)
  [21] J7AM_WKUP_CBASS_WKUP_0_J7AM_WKUP_CBASS_WKUP_MCU_SYSCLK0_6_CLK_EDC_CTRL_CBASS_INT_WKUP_MCU_SYSCLK0_6_BUSECC_1_ENABLE_CLR — Interrupt Enable Clear Register for j7am_wkup_cbass_wkup_0_j7am_wkup_cbass_wkup_mcu_sysclk0_6_clk_edc_ctrl_cbass_int_wkup_mcu_sysclk0_6_busecc_1_pend (access R/W1TC)
  [20] J7AM_WKUP_CBASS_WKUP_0_J7AM_WKUP_CBASS_IK3VTM_N16FFC_WKUP_0_VBUSP_P2P_BRIDGE_IK3VTM_N16FFC_WKUP_0_VBUSP_BRIDGE_BUSECC_ENABLE_CLR — Interrupt Enable Clear Register for j7am_wkup_cbass_wkup_0_j7am_wkup_cbass_Ik3vtm_n16ffc_wkup_0_vbusp_p2p_bridge_Ik3vtm_n16ffc_wkup_0_vbusp_bridge_busecc_pend (access R/W1TC)
  [19] J7AM_WKUP_CBASS_WKUP_0_J7AM_WKUP_CBASS_EXPORT_J7AM_WKUP_TO_MCU_VBUSM_L0_P2M_BRIDGE_EXPORT_J7AM_WKUP_TO_MCU_VBUSM_L0_BRIDGE_BUSECC_ENABLE_CLR — Interrupt Enable Clear Register for j7am_wkup_cbass_wkup_0_j7am_wkup_cbass_export_j7am_wkup_to_mcu_vbusm_l0_p2m_bridge_export_j7am_wkup_to_mcu_vbusm_l0_bridge_busecc_pend (access R/W1TC)
  [18] J7AM_WKUP_CBASS_WKUP_0_J7AM_WKUP_CBASS_BR_SCRP_32B_PCLK4_DMSC_TO_SCRP_32B_PCLK8_WAKEUP_L0_P2P_BRIDGE_BR_SCRP_32B_PCLK4_DMSC_TO_SCRP_32B_PCLK8_WAKEUP_L0_BRIDGE_DST_BUSECC_ENABLE_CLR — Interrupt Enable Clear Register for j7am_wkup_cbass_wkup_0_j7am_wkup_cbass_br_SCRP_32b_PCLK4_DMSC_to_SCRP_32b_PCLK8_wakeup_l0_p2p_bridge_br_SCRP_32b_PCLK4_DMSC_to_SCRP_32b_PCLK8_wakeup_l0_bridge_dst_busecc_pend (access R/W1TC)
  [17] J7AM_WKUP_CBASS_WKUP_0_J7AM_WKUP_CBASS_IJ7AM_WAKEUP_ECC_AGGR_WKUP_0_CFG_P2P_BRIDGE_IJ7AM_WAKEUP_ECC_AGGR_WKUP_0_CFG_BRIDGE_BUSECC_ENABLE_CLR — Interrupt Enable Clear Register for j7am_wkup_cbass_wkup_0_j7am_wkup_cbass_Ij7am_wakeup_ecc_aggr_wkup_0_cfg_p2p_bridge_Ij7am_wakeup_ecc_aggr_wkup_0_cfg_bridge_busecc_pend (access R/W1TC)
  [16] J7AM_WKUP_CBASS_WKUP_0_J7AM_WKUP_CBASS_CBASS_DEFAULT_ERR_J7AM_WKUP_CBASS_CBASS_DEFAULT_ERR_EDC_CTRL_BUSECC_ENABLE_CLR — Interrupt Enable Clear Register for j7am_wkup_cbass_wkup_0_j7am_wkup_cbass_cbass_default_err_j7am_wkup_cbass_cbass_default_err_edc_ctrl_busecc_pend (access R/W1TC)
  [15] J7AM_WKUP_CBASS_WKUP_0_J7AM_WKUP_CBASS_CBASS_DEFAULT_MMRS_J7AM_WKUP_CBASS_CBASS_DEFAULT_MMRS_EDC_CTRL_BUSECC_ENABLE_CLR — Interrupt Enable Clear Register for j7am_wkup_cbass_wkup_0_j7am_wkup_cbass_cbass_default_mmrs_j7am_wkup_cbass_cbass_default_mmrs_edc_ctrl_busecc_pend (access R/W1TC)
  [14] J7AM_WKUP_CBASS_WKUP_0_J7AM_WKUP_CBASS_ERR_SCR_J7AM_WKUP_CBASS_ERR_SCR_EDC_CTRL_BUSECC_ENABLE_CLR — Interrupt Enable Clear Register for j7am_wkup_cbass_wkup_0_j7am_wkup_cbass_err_scr_j7am_wkup_cbass_err_scr_edc_ctrl_busecc_pend (access R/W1TC)
  [13] J7AM_WKUP_CBASS_WKUP_0_J7AM_WKUP_CBASS_SCRP_32B_PCLK4_DMSC_SCR_J7AM_WKUP_CBASS_SCRP_32B_PCLK4_DMSC_SCR_EDC_CTRL_BUSECC_0_ENABLE_CLR — Interrupt Enable Clear Register for j7am_wkup_cbass_wkup_0_j7am_wkup_cbass_SCRP_32b_PCLK4_DMSC_scr_j7am_wkup_cbass_SCRP_32b_PCLK4_DMSC_scr_edc_ctrl_busecc_0_pend (access R/W1TC)
  [12] J7AM_WKUP_CBASS_WKUP_0_J7AM_WKUP_CBASS_EXPORT_J7AM_MCU_TO_WKUP_VBUSM_L0_M2P_BRIDGE_EXPORT_J7AM_MCU_TO_WKUP_VBUSM_L0_BRIDGE_BUSECC_ENABLE_CLR — Interrupt Enable Clear Register for j7am_wkup_cbass_wkup_0_j7am_wkup_cbass_export_j7am_mcu_to_wkup_vbusm_l0_m2p_bridge_export_j7am_mcu_to_wkup_vbusm_l0_bridge_busecc_pend (access R/W1TC)
  [11] J7AM_WKUP_CBASS_WKUP_0_J7AM_WKUP_CBASS_EXPORT_J7AM_WKUP_TO_MAIN_INFRA_VBUSP_L0_P2P_BRIDGE_EXPORT_J7AM_WKUP_TO_MAIN_INFRA_VBUSP_L0_BRIDGE_BUSECC_ENABLE_CLR — Interrupt Enable Clear Register for j7am_wkup_cbass_wkup_0_j7am_wkup_cbass_export_j7am_wkup_to_main_infra_vbusp_l0_p2p_bridge_export_j7am_wkup_to_main_infra_vbusp_l0_bridge_busecc_pend (access R/W1TC)
  [10] J7AM_WKUP_CBASS_WKUP_0_J7AM_WKUP_CBASS_WKUP_MCU_SYSCLK0_3_CLK_EDC_CTRL_CBASS_INT_WKUP_MCU_SYSCLK0_3_BUSECC_ENABLE_CLR — Interrupt Enable Clear Register for j7am_wkup_cbass_wkup_0_j7am_wkup_cbass_wkup_mcu_sysclk0_3_clk_edc_ctrl_cbass_int_wkup_mcu_sysclk0_3_busecc_pend (access R/W1TC)
  [9] J7AM_WKUP_CBASS_WKUP_0_J7AM_WKUP_CBASS_BR_SCRP_32B_PCLK4_DMSC_TO_SCRP_32B_PCLK8_WAKEUP_L0_P2P_BRIDGE_BR_SCRP_32B_PCLK4_DMSC_TO_SCRP_32B_PCLK8_WAKEUP_L0_BRIDGE_SRC_BUSECC_ENABLE_CLR — Interrupt Enable Clear Register for j7am_wkup_cbass_wkup_0_j7am_wkup_cbass_br_SCRP_32b_PCLK4_DMSC_to_SCRP_32b_PCLK8_wakeup_l0_p2p_bridge_br_SCRP_32b_PCLK4_DMSC_to_SCRP_32b_PCLK8_wakeup_l0_bridge_src_busecc_pend (access R/W1TC)
  [8] J7AM_WKUP_CBASS_WKUP_0_J7AM_WKUP_CBASS_CBASS_INT_DMSC_SCR_J7AM_WKUP_CBASS_CBASS_INT_DMSC_SCR_EDC_CTRL_BUSECC_ENABLE_CLR — Interrupt Enable Clear Register for j7am_wkup_cbass_wkup_0_j7am_wkup_cbass_cbass_int_dmsc_scr_j7am_wkup_cbass_cbass_int_dmsc_scr_edc_ctrl_busecc_pend (access R/W1TC)
  [7] J7AM_WKUP_CBASS_WKUP_0_J7AM_WKUP_CBASS_IJ7AM_WKUP_CBASS_WKUP_0_CBASS_ERR_SLV_P2P_BRIDGE_IJ7AM_WKUP_CBASS_WKUP_0_CBASS_ERR_SLV_BRIDGE_BUSECC_ENABLE_CLR — Interrupt Enable Clear Register for j7am_wkup_cbass_wkup_0_j7am_wkup_cbass_Ij7am_wkup_cbass_wkup_0_cbass_err_slv_p2p_bridge_Ij7am_wkup_cbass_wkup_0_cbass_err_slv_bridge_busecc_pend (access R/W1TC)
  [6] J7AM_WKUP_CBASS_WKUP_0_J7AM_WKUP_CBASS_WKUP_MCU_SYSCLK0_6_CLK_EDC_CTRL_CBASS_INT_WKUP_MCU_SYSCLK0_6_BUSECC_0_ENABLE_CLR — Interrupt Enable Clear Register for j7am_wkup_cbass_wkup_0_j7am_wkup_cbass_wkup_mcu_sysclk0_6_clk_edc_ctrl_cbass_int_wkup_mcu_sysclk0_6_busecc_0_pend (access R/W1TC)
  [5] J7AM_WKUP_CBASS_WKUP_0_J7AM_WKUP_CBASS_IJ7AM_WKUP_FW_CBASS_WKUP_0_CBASS_ERR_SLV_P2P_BRIDGE_IJ7AM_WKUP_FW_CBASS_WKUP_0_CBASS_ERR_SLV_BRIDGE_BUSECC_ENABLE_CLR — Interrupt Enable Clear Register for j7am_wkup_cbass_wkup_0_j7am_wkup_cbass_Ij7am_wkup_fw_cbass_wkup_0_cbass_err_slv_p2p_bridge_Ij7am_wkup_fw_cbass_wkup_0_cbass_err_slv_bridge_busecc_pend (access R/W1TC)
  [4] J7AM_WKUP_CBASS_WKUP_0_J7AM_WKUP_CBASS_ERR_SLV_P2P_BRIDGE_ERR_SLV_BRIDGE_BUSECC_ENABLE_CLR — Interrupt Enable Clear Register for j7am_wkup_cbass_wkup_0_j7am_wkup_cbass_err_slv_p2p_bridge_err_slv_bridge_busecc_pend (access R/W1TC)
  [3] J7AM_WKUP_CBASS_WKUP_0_J7AM_WKUP_CBASS_ISMS_WKUP_0_TIFS_VBUSP_S_P2P_BRIDGE_ISMS_WKUP_0_TIFS_VBUSP_S_BRIDGE_BUSECC_ENABLE_CLR — Interrupt Enable Clear Register for j7am_wkup_cbass_wkup_0_j7am_wkup_cbass_Isms_wkup_0_tifs_vbusp_s_p2p_bridge_Isms_wkup_0_tifs_vbusp_s_bridge_busecc_pend (access R/W1TC)
  [2] J7AM_WKUP_CBASS_WKUP_0_J7AM_WKUP_CBASS_ISMS_WKUP_0_HSM_VBUSP_S_P2P_BRIDGE_ISMS_WKUP_0_HSM_VBUSP_S_BRIDGE_BUSECC_ENABLE_CLR — Interrupt Enable Clear Register for j7am_wkup_cbass_wkup_0_j7am_wkup_cbass_Isms_wkup_0_hsm_vbusp_s_p2p_bridge_Isms_wkup_0_hsm_vbusp_s_bridge_busecc_pend (access R/W1TC)
  [1] J7AM_WKUP_CBASS_WKUP_0_J7AM_WKUP_CBASS_SCRP_32B_PCLK8_WAKEUP_SCR_J7AM_WKUP_CBASS_SCRP_32B_PCLK8_WAKEUP_SCR_EDC_CTRL_BUSECC_1_ENABLE_CLR — Interrupt Enable Clear Register for j7am_wkup_cbass_wkup_0_j7am_wkup_cbass_SCRP_32b_PCLK8_wakeup_scr_j7am_wkup_cbass_SCRP_32b_PCLK8_wakeup_scr_edc_ctrl_busecc_1_pend (access R/W1TC)
  [0] J7AM_WKUP_CBASS_WKUP_0_J7AM_WKUP_CBASS_IVDC_INFRA_SAFEG_VBUSP_32B_REF_WKUP2MAIN_INFRA_SAFEG_CFG_P2P_BRIDGE_IVDC_INFRA_SAFEG_VBUSP_32B_REF_WKUP2MAIN_INFRA_SAFEG_CFG_BRIDGE_BUSECC_ENABLE_CLR — Interrupt Enable Clear Register for j7am_wkup_cbass_wkup_0_j7am_wkup_cbass_Ivdc_infra_safeg_vbusp_32b_ref_wkup2main_infra_safeg_cfg_p2p_bridge_Ivdc_infra_safeg_vbusp_32b_ref_wkup2main_infra_safeg_cfg_bridge_busecc_pend (access R/W1TC)
0xC4 REGS_sec_enable_clr_reg1 — Interrupt Enable Clear Register 1
  [13] ECCAGG_ENABLE_CLR — Interrupt Enable Clear Register for eccagg_pend (access R/W1TC)
  [12] EFUSE_PARITY_CHAIN1_BUSECC_ENABLE_CLR — Interrupt Enable Clear Register for efuse_parity_chain1_busecc_pend (access R/W1TC)
  [11] J7_WKUP_FW_CBASS_WKUP_0_J7AM_WKUP_FW_CBASS_ERR_SCR_J7AM_WKUP_FW_CBASS_ERR_SCR_EDC_CTRL_BUSECC_ENABLE_CLR — Interrupt Enable Clear Register for j7_wkup_fw_cbass_wkup_0_j7am_wkup_fw_cbass_err_scr_j7am_wkup_fw_cbass_err_scr_edc_ctrl_busecc_pend (access R/W1TC)
  [10] J7_WKUP_FW_CBASS_WKUP_0_J7AM_WKUP_FW_CBASS_ERR_SLV_P2P_BRIDGE_ERR_SLV_BRIDGE_BUSECC_ENABLE_CLR — Interrupt Enable Clear Register for j7_wkup_fw_cbass_wkup_0_j7am_wkup_fw_cbass_err_slv_p2p_bridge_err_slv_bridge_busecc_pend (access R/W1TC)
  [9] J7_WKUP_FW_CBASS_WKUP_0_J7AM_WKUP_FW_CBASS_CBASS_DEFAULT_ERR_J7AM_WKUP_FW_CBASS_CBASS_DEFAULT_ERR_EDC_CTRL_BUSECC_ENABLE_CLR — Interrupt Enable Clear Register for j7_wkup_fw_cbass_wkup_0_j7am_wkup_fw_cbass_cbass_default_err_j7am_wkup_fw_cbass_cbass_default_err_edc_ctrl_busecc_pend (access R/W1TC)
  [8] J7_WKUP_FW_CBASS_WKUP_0_J7AM_WKUP_FW_CBASS_SCRP_WKUP_FW_CLK4_SCR_J7AM_WKUP_FW_CBASS_SCRP_WKUP_FW_CLK4_SCR_EDC_CTRL_BUSECC_ENABLE_CLR — Interrupt Enable Clear Register for j7_wkup_fw_cbass_wkup_0_j7am_wkup_fw_cbass_SCRP_wkup_fw_CLK4_scr_j7am_wkup_fw_cbass_SCRP_wkup_fw_CLK4_scr_edc_ctrl_busecc_pend (access R/W1TC)
  [n-1] J7AM_WKUP_CTRL_MMR_EDC_CTRL_BUSECC_{n}_ENABLE_CLR (n=1..8) — Interrupt Enable Clear Register for j7am_wkup_ctrl_mmr_edc_ctrl_busecc_{n}_pend (access R/W1TC)
0x13C REGS_ded_eoi_reg — EOI Register
  [0] EOI_WR — EOI Register (access R/W1TS)
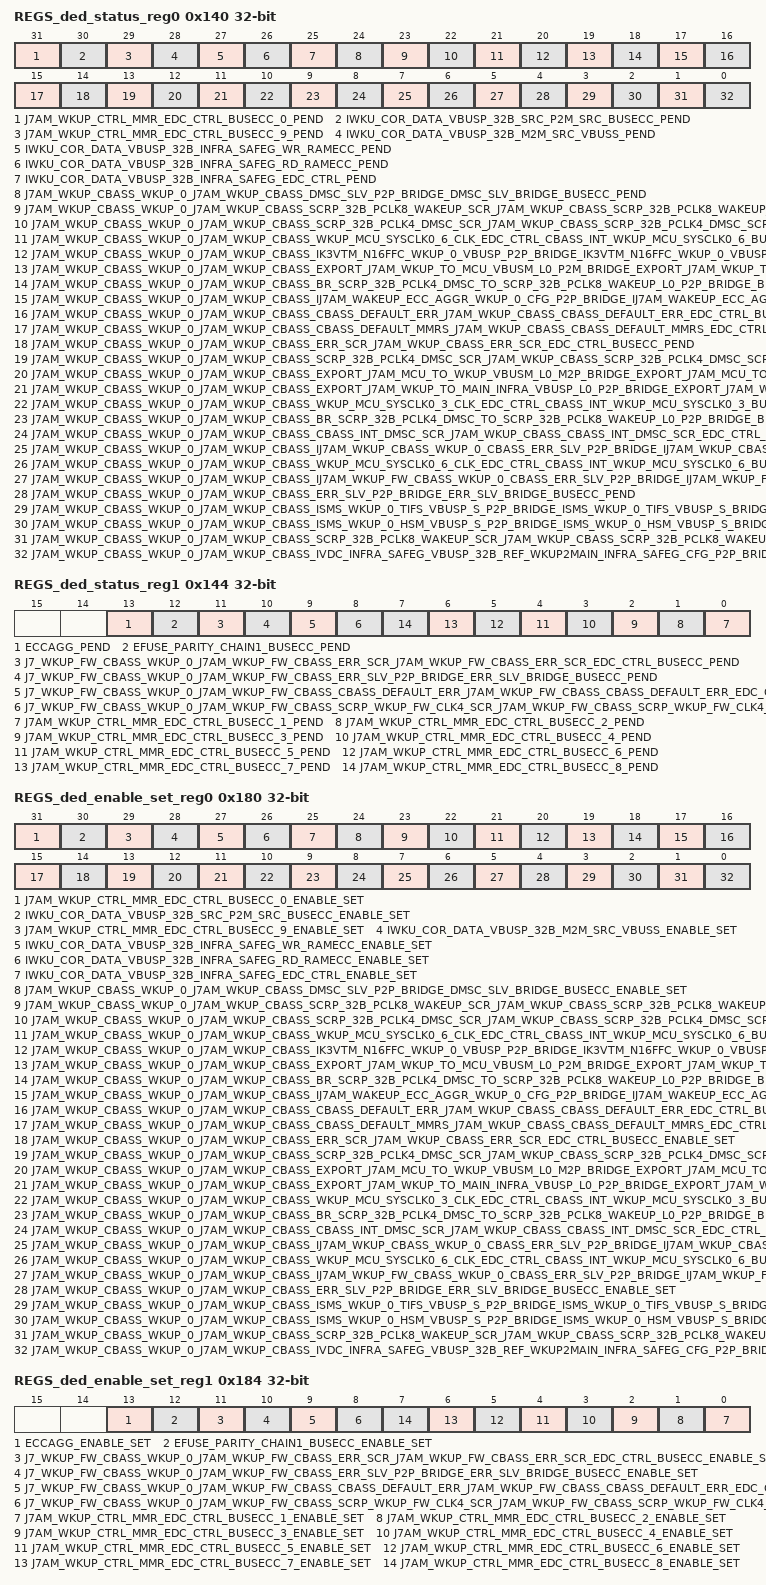
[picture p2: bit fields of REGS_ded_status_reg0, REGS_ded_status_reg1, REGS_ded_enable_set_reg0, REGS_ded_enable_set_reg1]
0x140 REGS_ded_status_reg0 — Interrupt Status Register 0
  fields as REGS_sec_status_reg0
0x144 REGS_ded_status_reg1 — Interrupt Status Register 1
  fields as REGS_sec_status_reg1
0x180 REGS_ded_enable_set_reg0 — Interrupt Enable Set Register 0
  fields as REGS_sec_enable_set_reg0
0x184 REGS_ded_enable_set_reg1 — Interrupt Enable Set Register 1
  fields as REGS_sec_enable_set_reg1
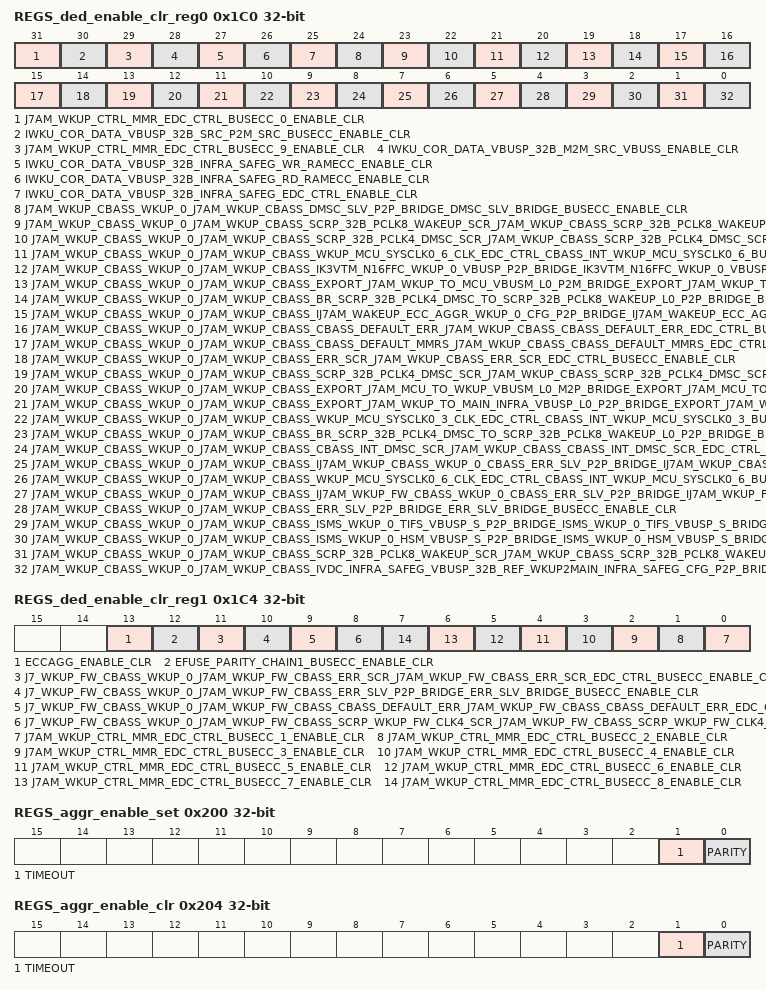
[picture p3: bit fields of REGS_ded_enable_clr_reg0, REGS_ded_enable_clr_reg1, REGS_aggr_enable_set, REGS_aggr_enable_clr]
0x1C0 REGS_ded_enable_clr_reg0 — Interrupt Enable Clear Register 0
  fields as REGS_sec_enable_clr_reg0
0x1C4 REGS_ded_enable_clr_reg1 — Interrupt Enable Clear Register 1
  fields as REGS_sec_enable_clr_reg1
0x200 REGS_aggr_enable_set — AGGR interrupt enable set Register
  [1] TIMEOUT — interrupt enable set for svbus timeout errors (access R/W1TS)
  [0] PARITY — interrupt enable set for parity errors (access R/W1TS)
0x204 REGS_aggr_enable_clr — AGGR interrupt enable clear Register
  [1] TIMEOUT — interrupt enable clear for svbus timeout errors (access R/W1TC)
  [0] PARITY — interrupt enable clear for parity errors (access R/W1TC)
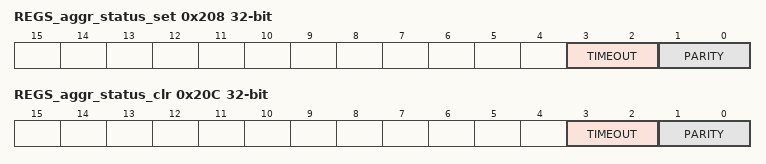
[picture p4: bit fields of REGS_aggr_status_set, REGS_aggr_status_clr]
0x208 REGS_aggr_status_set — AGGR interrupt status set Register
  [3:2] TIMEOUT — interrupt status set for svbus timeout errors (access R/WI)
  [1:0] PARITY — interrupt status set for parity errors (access R/WI)
0x20C REGS_aggr_status_clr — AGGR interrupt status clear Register
  [3:2] TIMEOUT — interrupt status clear for svbus timeout errors (access R/WD)
  [1:0] PARITY — interrupt status clear for parity errors (access R/WD)
